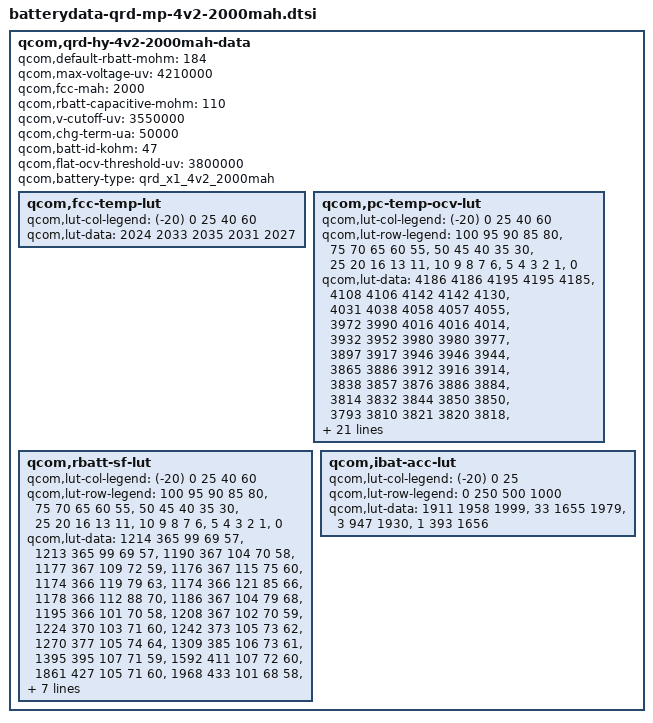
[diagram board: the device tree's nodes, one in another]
/* Copyright (c) 2014, The Linux Foundation. All rights reserved.
 *
 * This program is free software; you can redistribute it and/or modify
 * it under the terms of the GNU General Public License version 2 and
 * only version 2 as published by the Free Software Foundation.
 *
 * This program is distributed in the hope that it will be useful,
 * but WITHOUT ANY WARRANTY; without even the implied warranty of
 * MERCHANTABILITY or FITNESS FOR A PARTICULAR PURPOSE.  See the
 * GNU General Public License for more details.
 */

qcom,qrd-hy-4v2-2000mah-data {
	qcom,default-rbatt-mohm = <184>;
	qcom,max-voltage-uv = <4210000>;
	qcom,fcc-mah = <2000>;
	qcom,rbatt-capacitive-mohm = <110>;
	qcom,v-cutoff-uv = <3550000>;
	qcom,chg-term-ua = <50000>;
	qcom,batt-id-kohm = <47>;
	qcom,flat-ocv-threshold-uv = <3800000>;
	qcom,battery-type = "qrd_x1_4v2_2000mah";

	qcom,fcc-temp-lut {
		qcom,lut-col-legend = <(-20) 0 25 40 60>;
		qcom,lut-data = <2024 2033 2035 2031 2027>;
	};

	qcom,pc-temp-ocv-lut {
		qcom,lut-col-legend = <(-20) 0 25 40 60>;
		qcom,lut-row-legend = <100 95 90 85 80>,
				<75 70 65 60 55>,
				<50 45 40 35 30>,
				<25 20 16 13 11>,
				<10 9 8 7 6>,
				<5 4 3 2 1 >,
				<0>;
		qcom,lut-data = <4186 4186 4195 4195 4185>,
				<4108 4106 4142 4142 4130>,
				<4031 4038 4058 4057 4055>,
				<3972 3990 4016 4016 4014>,
				<3932 3952 3980 3980 3977>,
				<3897 3917 3946 3946 3944>,
				<3865 3886 3912 3916 3914>,
				<3838 3857 3876 3886 3884>,
				<3814 3832 3844 3850 3850>,
				<3793 3810 3821 3820 3818>,
				<3776 3790 3803 3802 3800>,
				<3762 3774 3788 3788 3786>,
				<3748 3763 3776 3777 3774>,
				<3733 3752 3766 3766 3764>,
				<3716 3744 3756 3754 3746>,
				<3694 3734 3744 3738 3726>,
				<3668 3721 3726 3720 3708>,
				<3640 3706 3704 3700 3686>,
				<3616 3692 3687 3679 3666>,
				<3595 3678 3680 3672 3660>,
				<3582 3669 3678 3670 3658>,
				<3567 3660 3674 3668 3656>,
				<3550 3647 3669 3664 3652>,
				<3531 3632 3662 3657 3644>,
				<3507 3610 3644 3642 3628>,
				<3480 3581 3609 3608 3592>,
				<3446 3542 3559 3560 3543>,
				<3402 3488 3492 3495 3480>,
				<3340 3406 3401 3410 3396>,
	            <3236 3263 3259 3281 3270>,
                <3000 3000 3000 3015 3000>;
	};
	qcom,rbatt-sf-lut {
		qcom,lut-col-legend = <(-20) 0 25 40 60>;
		qcom,lut-row-legend = <100 95 90 85 80>,
				<75 70 65 60 55>,
				<50 45 40 35 30>,
				<25 20 16 13 11>,
				<10 9 8 7 6>,
				<5  4 3 2 1>,
				<0>;
		qcom,lut-data = < 1214 365 99 69 57>,
				<1213 365 99 69 57>,
				<1190 367 104 70 58>,
				<1177 367 109 72 59>,
				<1176 367 115 75 60>,
				<1174 366 119 79 63>,
				<1174 366 121 85 66>,
				<1178 366 112 88 70>,
				<1186 367 104 79 68>,
				<1195 366 101 70 58>,
				<1208 367 102 70 59>,
				<1224 370 103 71 60>,
				<1242 373 105 73 62>,
				<1270 377 105 74 64>,
				<1309 385 106 73 61>,
				<1395 395 107 71 59>,
				<1592 411 107 72 60>,
				<1861 427 105 71 60>,
				<1968 433 101 68 58>,
				<2377 448 102 69 58>,
				<2660 448 104 71 59>,
				<3034 466 107 72 61>,
				<3509 487 112 74 64>,
				<4240 527 117 77 65>,
				<5272 579 121 78 64>,
				<6759 666 120 76 62>,
				<9195 805 122 76 62>,
				<13555 1037 130 79 64>,
				<21792 1618 149 85 68>,
                <39904 3237 227 112 91>,
                <79808 6474 454 224 183>;
	};
	qcom,ibat-acc-lut {
		qcom,lut-col-legend = <(-20) 0 25>;
		qcom,lut-row-legend = <0 250 500 1000>;
		qcom,lut-data = <1911 1958 1999>,
				<33 1655 1979>,
				<3 947 1930>,
				<1 393 1656>;
	};
};
